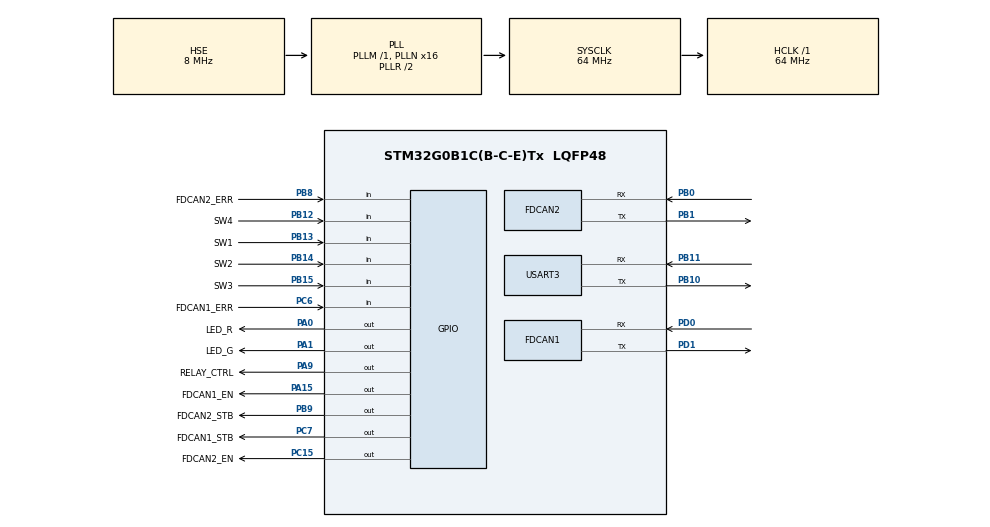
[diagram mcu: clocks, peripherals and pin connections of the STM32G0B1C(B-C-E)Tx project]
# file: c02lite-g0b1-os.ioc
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FDCAN1.AutoRetransmission=ENABLE
FDCAN1.CalculateBaudRateNominal=500000
FDCAN1.CalculateTimeBitNominal=2000
FDCAN1.CalculateTimeQuantumNominal=125.0
FDCAN1.ClockDivider=FDCAN_CLOCK_DIV1
FDCAN1.DataPrescaler=2
FDCAN1.DataSyncJumpWidth=7
FDCAN1.DataTimeSeg1=8
FDCAN1.DataTimeSeg2=7
FDCAN1.ExtFiltersNbr=1
FDCAN1.FrameFormat=FDCAN_FRAME_FD_BRS
FDCAN1.NominalPrescaler=8
FDCAN1.NominalSyncJumpWidth=7
FDCAN1.NominalTimeSeg1=8
FDCAN1.NominalTimeSeg2=7
FDCAN1.StdFiltersNbr=0
FDCAN1.TransmitPause=ENABLE
FDCAN2.AutoRetransmission=ENABLE
FDCAN2.CalculateBaudRateNominal=500000
FDCAN2.CalculateTimeBitNominal=2000
FDCAN2.CalculateTimeQuantumNominal=125.0
FDCAN2.DataPrescaler=2
FDCAN2.DataSyncJumpWidth=7
FDCAN2.DataTimeSeg1=8
FDCAN2.DataTimeSeg2=7
FDCAN2.ExtFiltersNbr=1
FDCAN2.FrameFormat=FDCAN_FRAME_FD_BRS
FDCAN2.NominalPrescaler=8
FDCAN2.NominalSyncJumpWidth=7
FDCAN2.NominalTimeSeg1=8
FDCAN2.NominalTimeSeg2=7
FDCAN2.StdFiltersNbr=0
FDCAN2.TransmitPause=ENABLE
FREERTOS.Tasks01=defaultTask,0,128,StartDefaultTask,Default,NULL,Dynamic,NULL,NULL
IWDG.Prescaler=IWDG_PRESCALER_32
Mcu.Family=STM32G0
Mcu.Name=STM32G0B1C(B-C-E)Tx
Mcu.Package=LQFP48
NVIC.TIM16_FDCAN_IT0_IRQn=true\:0\:0\:false\:false\:true\:false\:true\:true\:true
NVIC.TIM1_BRK_UP_TRG_COM_IRQn=true\:3\:0\:false\:false\:true\:false\:false\:true\:true
NVIC.TIM2_IRQn=true\:1\:0\:true\:false\:true\:false\:true\:true\:true
NVIC.TIM3_TIM4_IRQn=true\:1\:0\:true\:false\:true\:false\:true\:true\:true
NVIC.TimeBase=TIM1_BRK_UP_TRG_COM_IRQn
NVIC.TimeBaseIP=TIM1
NVIC.USART3_4_5_6_LPUART1_IRQn=true\:2\:0\:true\:false\:true\:false\:true\:true\:true
PA0.GPIO_Label=LED_R
PA0.GPIO_Speed=GPIO_SPEED_FREQ_LOW
PA0.PinState=GPIO_PIN_SET
PA0.Signal=GPIO_Output
PA1.GPIO_Label=LED_G
PA1.PinState=GPIO_PIN_SET
PA1.Signal=GPIO_Output
PA13.Mode=Serial_Wire
PA13.Signal=SYS_SWDIO
PA14-BOOT0.Mode=Serial_Wire
PA14-BOOT0.Signal=SYS_SWCLK
PA15.GPIO_Label=FDCAN1_EN
PA15.PinState=GPIO_PIN_RESET
PA15.Signal=GPIO_Output
PA9.GPIO_Label=RELAY_CTRL
PA9.Signal=GPIO_Output
PB0.Mode=FDCAN_Activate
PB0.Signal=FDCAN2_RX
PB1.Mode=FDCAN_Activate
PB1.Signal=FDCAN2_TX
PB10.Mode=Asynchronous
PB10.Signal=USART3_TX
PB11.Mode=Asynchronous
PB11.Signal=USART3_RX
PB12.GPIO_Label=SW4
PB12.Signal=GPIO_Input
PB13.GPIO_Label=SW1
PB13.Signal=GPIO_Input
PB14.GPIO_Label=SW2
PB14.Signal=GPIO_Input
PB15.GPIO_Label=SW3
PB15.Signal=GPIO_Input
PB8.GPIO_Label=FDCAN2_ERR
PB8.GPIO_PuPd=GPIO_PULLUP
PB8.Signal=GPIO_Input
PB9.GPIO_Label=FDCAN2_STB
PB9.GPIO_PuPd=GPIO_NOPULL
PB9.PinState=GPIO_PIN_RESET
PB9.Signal=GPIO_Output
PC15-OSC32_OUT\ (PC15).GPIO_Label=FDCAN2_EN
PC15-OSC32_OUT\ (PC15).Signal=GPIO_Output
PC6.GPIO_Label=FDCAN1_ERR
PC6.GPIO_PuPd=GPIO_PULLUP
PC6.Signal=GPIO_Input
PC7.GPIO_Label=FDCAN1_STB
PC7.GPIO_PuPd=GPIO_NOPULL
PC7.Signal=GPIO_Output
PD0.Mode=FDCAN_Activate
PD0.Signal=FDCAN1_RX
PD1.Mode=FDCAN_Activate
PD1.Signal=FDCAN1_TX
PF0-OSC_IN\ (PF0).Mode=HSE-External-Oscillator
PF0-OSC_IN\ (PF0).Signal=RCC_OSC_IN
PF1-OSC_OUT\ (PF1).Mode=HSE-External-Oscillator
PF1-OSC_OUT\ (PF1).Signal=RCC_OSC_OUT
ProjectManager.HeapSize=0x200
ProjectManager.StackSize=0x400
ProjectManager.TargetToolchain=STM32CubeIDE
RCC.ADCFreq_Value=64000000
RCC.AHBFreq_Value=64000000
RCC.CortexFreq_Value=64000000
RCC.EXTERNAL_CLOCK_VALUE=48000
RCC.EnbaleCSS=true
RCC.HCLKFreq_Value=64000000
RCC.HSE_VALUE=8000000
RCC.HSI48_VALUE=48000000
RCC.HSI_VALUE=16000000
RCC.LSE_VALUE=32768
RCC.PLLN=16
RCC.PLLSourceVirtual=RCC_PLLSOURCE_HSE
RCC.SYSCLKFreq_VALUE=64000000
RCC.SYSCLKSource=RCC_SYSCLKSOURCE_PLLCLK
RCC.USBFreq_Value=48000000
RCC.VCOOutputFreq_Value=128000000
TIM2.AutoReloadPreload=TIM_AUTORELOAD_PRELOAD_ENABLE
TIM2.CounterMode=TIM_COUNTERMODE_UP
TIM2.Period=1999
TIM2.Prescaler=6399
TIM3.AutoReloadPreload=TIM_AUTORELOAD_PRELOAD_ENABLE
TIM3.CounterMode=TIM_COUNTERMODE_UP
TIM3.Period=39999
TIM3.Prescaler=6399
USART3.VirtualMode-Asynchronous=VM_ASYNC
VP_FREERTOS_VS_CMSIS_V1.Mode=CMSIS_V1
VP_IWDG_VS_IWDG.Mode=IWDG_Activate
VP_SYS_VS_DBSignals.Mode=DisableDeadBatterySignals
VP_SYS_VS_tim1.Mode=TIM1
VP_TIM2_VS_ClockSourceINT.Mode=Internal
VP_TIM3_VS_ClockSourceINT.Mode=Internal
board=custom

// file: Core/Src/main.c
/* USER CODE BEGIN Header */
/**
  ******************************************************************************
  * @file           : main.c
  * @brief          : Main program body
  ******************************************************************************
  * @attention
  *
  * Copyright (c) 2023 STMicroelectronics.
  * All rights reserved.
  *
  * This software is licensed under terms that can be found in the LICENSE file
  * in the root directory of this software component.
  * If no LICENSE file comes with this software, it is provided AS-IS.
  *
  ******************************************************************************
  */
/* USER CODE END Header */
#include "main.h"
#include "cmsis_os.h"
#include "fdcan.h"
#include "iwdg.h"
#include "tim.h"
#include "usart.h"
#include "gpio.h"

/* USER CODE BEGIN Includes */
#include "includes.h"
/* USER CODE END Includes */

void SystemClock_Config(void);
void MX_FREERTOS_Init(void);

int main(void)
{

  /* MCU Configuration--------------------------------------------------------*/

  /* Reset of all peripherals, Initializes the Flash interface and the Systick. */
  HAL_Init();

  /* Configure the system clock */
  SystemClock_Config();

  /* Initialize all configured peripherals */
  MX_GPIO_Init();
  MX_FDCAN1_Init();
  MX_FDCAN2_Init();
  MX_USART3_UART_Init();
  MX_TIM2_Init();
  MX_TIM3_Init();
  MX_IWDG_Init();
  /* USER CODE BEGIN 2 */
  printf("hello\n");
  appMain();
  /* USER CODE END 2 */

  /* Call init function for freertos objects (in freertos.c) */
  MX_FREERTOS_Init();

  /* Start scheduler */
  osKernelStart();

  /* We should never get here as control is now taken by the scheduler */
  /* Infinite loop */
  while (1)
  {

  }
}

void SystemClock_Config(void)
{
  RCC_OscInitTypeDef RCC_OscInitStruct = {0};
  RCC_ClkInitTypeDef RCC_ClkInitStruct = {0};

  /** Configure the main internal regulator output voltage
  */
  HAL_PWREx_ControlVoltageScaling(PWR_REGULATOR_VOLTAGE_SCALE1);

  /** Initializes the RCC Oscillators according to the specified parameters
  * in the RCC_OscInitTypeDef structure.
  */
  RCC_OscInitStruct.OscillatorType = RCC_OSCILLATORTYPE_LSI|RCC_OSCILLATORTYPE_HSE;
  RCC_OscInitStruct.HSEState = RCC_HSE_ON;
  RCC_OscInitStruct.LSIState = RCC_LSI_ON;
  RCC_OscInitStruct.PLL.PLLState = RCC_PLL_ON;
  RCC_OscInitStruct.PLL.PLLSource = RCC_PLLSOURCE_HSE;
  RCC_OscInitStruct.PLL.PLLM = RCC_PLLM_DIV1;
  RCC_OscInitStruct.PLL.PLLN = 16;
  RCC_OscInitStruct.PLL.PLLP = RCC_PLLP_DIV2;
  RCC_OscInitStruct.PLL.PLLQ = RCC_PLLQ_DIV2;
  RCC_OscInitStruct.PLL.PLLR = RCC_PLLR_DIV2;
  if (HAL_RCC_OscConfig(&RCC_OscInitStruct) != HAL_OK)
  {
    Error_Handler();
  }

  /** Initializes the CPU, AHB and APB buses clocks
  */
  RCC_ClkInitStruct.ClockType = RCC_CLOCKTYPE_HCLK|RCC_CLOCKTYPE_SYSCLK
                              |RCC_CLOCKTYPE_PCLK1;
  RCC_ClkInitStruct.SYSCLKSource = RCC_SYSCLKSOURCE_PLLCLK;
  RCC_ClkInitStruct.AHBCLKDivider = RCC_SYSCLK_DIV1;
  RCC_ClkInitStruct.APB1CLKDivider = RCC_HCLK_DIV1;

  if (HAL_RCC_ClockConfig(&RCC_ClkInitStruct, FLASH_LATENCY_2) != HAL_OK)
  {
    Error_Handler();
  }

  /** Enables the Clock Security System
  */
  HAL_RCC_EnableCSS();
}

//void HAL_TIM_PeriodElapsedCallback(TIM_HandleTypeDef *htim)
//{
//  /* USER CODE BEGIN Callback 0 */
//
//  /* USER CODE END Callback 0 */
//  if (htim->Instance == TIM1) {
//    HAL_IncTick();
//  }
//  /* USER CODE BEGIN Callback 1 */
//
//  /* USER CODE END Callback 1 */
//}

void Error_Handler(void)
{
  /* USER CODE BEGIN Error_Handler_Debug */
  /* User can add his own implementation to report the HAL error return state */
  __disable_irq();
  while (1)
  {
	  printf("error\n");
  }
  /* USER CODE END Error_Handler_Debug */
}
